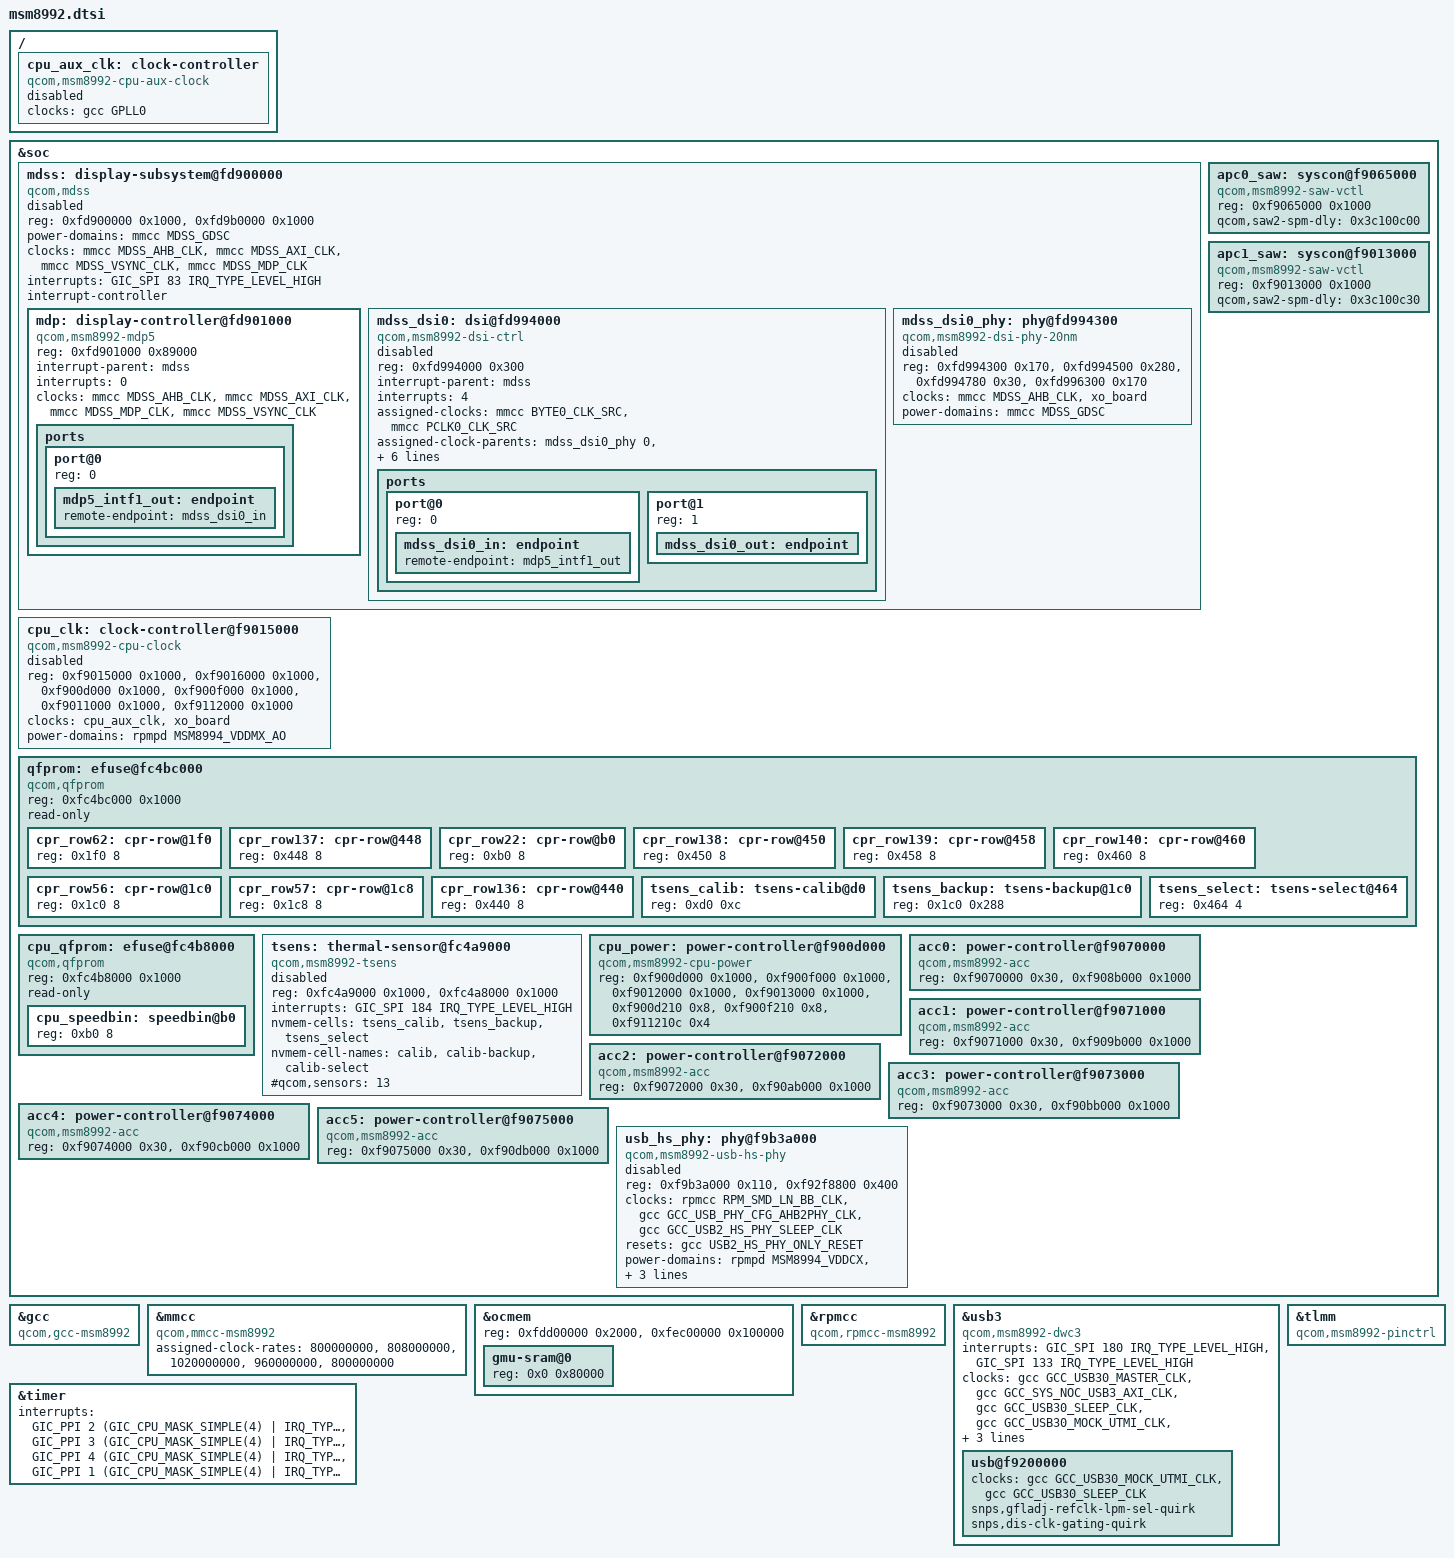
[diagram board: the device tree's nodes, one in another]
// SPDX-License-Identifier: GPL-2.0-only
/*
 * Copyright (c) 2013-2016, The Linux Foundation. All rights reserved.
 */

#include "msm8994.dtsi"

/ {
	cpu_aux_clk: clock-controller {
		compatible = "qcom,msm8992-cpu-aux-clock";
		clocks = <&gcc GPLL0>;
		clock-names = "aux";
		#clock-cells = <0>;
		status = "disabled";
	};
};

/* 8992 only features 2 A57 cores. */
/delete-node/ &CPU6;
/delete-node/ &CPU7;
/delete-node/ &cpu6_map;
/delete-node/ &cpu7_map;

&soc {
	mdss: display-subsystem@fd900000 {
		compatible = "qcom,mdss";
		reg = <0xfd900000 0x1000>, <0xfd9b0000 0x1000>;
		reg-names = "mdss_phys", "vbif_phys";
		power-domains = <&mmcc MDSS_GDSC>;
		clocks = <&mmcc MDSS_AHB_CLK>, <&mmcc MDSS_AXI_CLK>,
			 <&mmcc MDSS_VSYNC_CLK>, <&mmcc MDSS_MDP_CLK>;
		clock-names = "iface", "bus", "vsync", "core";
		interrupts = <GIC_SPI 83 IRQ_TYPE_LEVEL_HIGH>;
		interrupt-controller;
		#interrupt-cells = <1>;
		#address-cells = <1>;
		#size-cells = <1>;
		ranges;
		status = "disabled";

		mdp: display-controller@fd901000 {
			compatible = "qcom,msm8992-mdp5", "qcom,mdp5";
			reg = <0xfd901000 0x89000>;
			reg-names = "mdp_phys";
			interrupt-parent = <&mdss>;
			interrupts = <0>;
			clocks = <&mmcc MDSS_AHB_CLK>, <&mmcc MDSS_AXI_CLK>,
				 <&mmcc MDSS_MDP_CLK>, <&mmcc MDSS_VSYNC_CLK>;
			clock-names = "iface", "bus", "core", "vsync";

			ports {
				#address-cells = <1>;
				#size-cells = <0>;
				port@0 {
					reg = <0>;
					mdp5_intf1_out: endpoint {
						remote-endpoint = <&mdss_dsi0_in>;
					};
				};
			};
		};

		mdss_dsi0: dsi@fd994000 {
			compatible = "qcom,msm8992-dsi-ctrl", "qcom,mdss-dsi-ctrl";
			reg = <0xfd994000 0x300>;
			reg-names = "dsi_ctrl";
			interrupt-parent = <&mdss>;
			interrupts = <4>;
			assigned-clocks = <&mmcc BYTE0_CLK_SRC>, <&mmcc PCLK0_CLK_SRC>;
			assigned-clock-parents = <&mdss_dsi0_phy 0>, <&mdss_dsi0_phy 1>;
			clocks = <&mmcc MDSS_MDP_CLK>, <&mmcc MDSS_AHB_CLK>,
				 <&mmcc MDSS_AXI_CLK>, <&mmcc MDSS_BYTE0_CLK>,
				 <&mmcc MDSS_PCLK0_CLK>, <&mmcc MDSS_ESC0_CLK>,
				 <&mmcc MMSS_MISC_AHB_CLK>;
			clock-names = "mdp_core", "iface", "bus", "byte", "pixel",
				      "core", "core_mmss";
			phys = <&mdss_dsi0_phy>;
			#address-cells = <1>;
			#size-cells = <0>;
			status = "disabled";
			ports {
				#address-cells = <1>;
				#size-cells = <0>;
				port@0 {
					reg = <0>;
					mdss_dsi0_in: endpoint {
						remote-endpoint = <&mdp5_intf1_out>;
					};
				};
				port@1 {
					reg = <1>;
					mdss_dsi0_out: endpoint { };
				};
			};
		};

		mdss_dsi0_phy: phy@fd994300 {
			compatible = "qcom,msm8992-dsi-phy-20nm";
			reg = <0xfd994300 0x170>, <0xfd994500 0x280>,
			      <0xfd994780 0x30>, <0xfd996300 0x170>;
			reg-names = "dsi_pll", "dsi_phy", "dsi_phy_regulator", "dsi_pll_aux";
			#clock-cells = <1>;
			#phy-cells = <0>;
			clocks = <&mmcc MDSS_AHB_CLK>, <&xo_board>;
			clock-names = "iface", "ref";
			power-domains = <&mmcc MDSS_GDSC>;
			status = "disabled";
		};
	};

	cpu_clk: clock-controller@f9015000 {
		compatible = "qcom,msm8992-cpu-clock";
		reg = <0xf9015000 0x1000>, <0xf9016000 0x1000>,
		      <0xf900d000 0x1000>, <0xf900f000 0x1000>,
		      <0xf9011000 0x1000>, <0xf9112000 0x1000>;
		reg-names = "a53-pll", "a57-pll", "a53-mux", "a57-mux",
			    "cci-pll", "cci-mux";
		clocks = <&cpu_aux_clk>, <&xo_board>;
		clock-names = "aux", "xo";
		power-domains = <&rpmpd MSM8994_VDDMX_AO>;
		#clock-cells = <1>;
		status = "disabled";
	};

	apc0_saw: syscon@f9065000 {
		compatible = "qcom,msm8992-saw-vctl", "syscon";
		reg = <0xf9065000 0x1000>;
		qcom,saw2-spm-dly = <0x3c100c00>;
	};

	apc1_saw: syscon@f9013000 {
		compatible = "qcom,msm8992-saw-vctl", "syscon";
		reg = <0xf9013000 0x1000>;
		qcom,saw2-spm-dly = <0x3c100c30>;
	};

	qfprom: efuse@fc4bc000 {
		compatible = "qcom,qfprom";
		reg = <0xfc4bc000 0x1000>;
		#address-cells = <1>;
		#size-cells = <1>;
		read-only;
		cpr_row62: cpr-row@1f0 { reg = <0x1f0 8>; };
		cpr_row137: cpr-row@448 { reg = <0x448 8>; };
		cpr_row22: cpr-row@b0 { reg = <0xb0 8>; };
		cpr_row138: cpr-row@450 { reg = <0x450 8>; };
		cpr_row139: cpr-row@458 { reg = <0x458 8>; };
		cpr_row140: cpr-row@460 { reg = <0x460 8>; };
		cpr_row56: cpr-row@1c0 { reg = <0x1c0 8>; };
		cpr_row57: cpr-row@1c8 { reg = <0x1c8 8>; };
		cpr_row136: cpr-row@440 { reg = <0x440 8>; };

		tsens_calib: tsens-calib@d0 { reg = <0xd0 0xc>; };
		tsens_backup: tsens-backup@1c0 { reg = <0x1c0 0x288>; };
		tsens_select: tsens-select@464 { reg = <0x464 4>; };
	};

	cpu_qfprom: efuse@fc4b8000 {
		compatible = "qcom,qfprom";
		reg = <0xfc4b8000 0x1000>;
		#address-cells = <1>;
		#size-cells = <1>;
		read-only;
		cpu_speedbin: speedbin@b0 { reg = <0xb0 8>; };
	};

	tsens: thermal-sensor@fc4a9000 {
		compatible = "qcom,msm8992-tsens";
		reg = <0xfc4a9000 0x1000>, <0xfc4a8000 0x1000>;
		interrupts = <GIC_SPI 184 IRQ_TYPE_LEVEL_HIGH>;
		interrupt-names = "uplow";
		nvmem-cells = <&tsens_calib>, <&tsens_backup>, <&tsens_select>;
		nvmem-cell-names = "calib", "calib-backup", "calib-select";
		#thermal-sensor-cells = <1>;
		#qcom,sensors = <13>;
		status = "disabled";
	};

	cpu_power: power-controller@f900d000 {
		compatible = "qcom,msm8992-cpu-power";
		reg = <0xf900d000 0x1000>, <0xf900f000 0x1000>,
		      <0xf9012000 0x1000>, <0xf9013000 0x1000>,
		      <0xf900d210 0x8>, <0xf900f210 0x8>,
		      <0xf911210c 0x4>;
		reg-names = "a53-l2", "a57-l2", "a53-saw", "a57-saw",
			    "a53-q2s", "a57-q2s", "l2-kick";
	};

	acc0: power-controller@f9070000 {
		compatible = "qcom,msm8992-acc";
		reg = <0xf9070000 0x30>, <0xf908b000 0x1000>;
		reg-names = "ldo", "acc";
	};

	acc1: power-controller@f9071000 {
		compatible = "qcom,msm8992-acc";
		reg = <0xf9071000 0x30>, <0xf909b000 0x1000>;
		reg-names = "ldo", "acc";
	};

	acc2: power-controller@f9072000 {
		compatible = "qcom,msm8992-acc";
		reg = <0xf9072000 0x30>, <0xf90ab000 0x1000>;
		reg-names = "ldo", "acc";
	};

	acc3: power-controller@f9073000 {
		compatible = "qcom,msm8992-acc";
		reg = <0xf9073000 0x30>, <0xf90bb000 0x1000>;
		reg-names = "ldo", "acc";
	};

	acc4: power-controller@f9074000 {
		compatible = "qcom,msm8992-acc";
		reg = <0xf9074000 0x30>, <0xf90cb000 0x1000>;
		reg-names = "ldo", "acc";
	};

	acc5: power-controller@f9075000 {
		compatible = "qcom,msm8992-acc";
		reg = <0xf9075000 0x30>, <0xf90db000 0x1000>;
		reg-names = "ldo", "acc";
	};

	usb_hs_phy: phy@f9b3a000 {
		compatible = "qcom,msm8992-usb-hs-phy";
		reg = <0xf9b3a000 0x110>, <0xf92f8800 0x400>;
		reg-names = "phy-csr", "qscratch";
		#phy-cells = <0>;
		clocks = <&rpmcc RPM_SMD_LN_BB_CLK>,
			 <&gcc GCC_USB_PHY_CFG_AHB2PHY_CLK>,
			 <&gcc GCC_USB2_HS_PHY_SLEEP_CLK>;
		clock-names = "ref", "ahb", "sleep";
		resets = <&gcc USB2_HS_PHY_ONLY_RESET>;
		power-domains = <&rpmpd MSM8994_VDDCX>, <&rpmpd MSM8994_VDDMX>;
		power-domain-names = "cx", "mx";
		required-opps = <&rpmpd_opp_nom>, <&rpmpd_opp_nom>;
		qcom,hsphy-init = <0x00d191a4>;
		status = "disabled";
	};
};

&gcc {
	compatible = "qcom,gcc-msm8992";
};

&mmcc {
	compatible = "qcom,mmcc-msm8992";

	assigned-clock-rates = <800000000>,
			       <808000000>,
			       <1020000000>,
			       <960000000>,
			       <800000000>;
};

&ocmem {
	reg = <0xfdd00000 0x2000>, <0xfec00000 0x100000>;

	gmu-sram@0 {
		reg = <0x0 0x80000>;
	};
};

&rpmcc {
	compatible = "qcom,rpmcc-msm8992", "qcom,rpmcc";
};

&usb3 {
	compatible = "qcom,msm8992-dwc3", "qcom,dwc3";
	interrupts = <GIC_SPI 180 IRQ_TYPE_LEVEL_HIGH>,
		     <GIC_SPI 133 IRQ_TYPE_LEVEL_HIGH>;
	interrupt-names = "pwr_event", "hs_phy_irq";
	clocks = <&gcc GCC_USB30_MASTER_CLK>,
		 <&gcc GCC_SYS_NOC_USB3_AXI_CLK>,
		 <&gcc GCC_USB30_SLEEP_CLK>,
		 <&gcc GCC_USB30_MOCK_UTMI_CLK>,
		 <&rpmcc RPM_SMD_XO_CLK_SRC>;
	clock-names = "core", "iface", "sleep", "mock_utmi", "xo";
	assigned-clock-rates = <19200000>, <125000000>;
	resets = <&gcc USB30_RESET>;

	usb@f9200000 {
		clocks = <&gcc GCC_USB30_MOCK_UTMI_CLK>, <&gcc GCC_USB30_SLEEP_CLK>;
		clock-names = "ref", "suspend";
		snps,gfladj-refclk-lpm-sel-quirk;
		snps,dis-clk-gating-quirk;
	};
};

&timer {
	interrupts = <GIC_PPI 2 (GIC_CPU_MASK_SIMPLE(4) | IRQ_TYPE_LEVEL_LOW)>,
			     <GIC_PPI 3 (GIC_CPU_MASK_SIMPLE(4) | IRQ_TYPE_LEVEL_LOW)>,
			     <GIC_PPI 4 (GIC_CPU_MASK_SIMPLE(4) | IRQ_TYPE_LEVEL_LOW)>,
			     <GIC_PPI 1 (GIC_CPU_MASK_SIMPLE(4) | IRQ_TYPE_LEVEL_LOW)>;
};

&tlmm {
	compatible = "qcom,msm8992-pinctrl";
};
